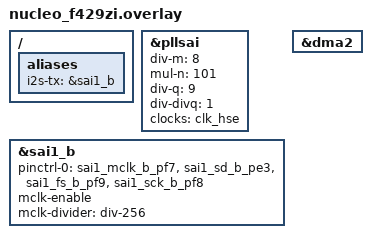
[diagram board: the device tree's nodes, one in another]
/*
 * Copyright (c) 2025 Mario Paja
 *
 * SPDX-License-Identifier: Apache-2.0
 */

/ {
	aliases {
		i2s-tx = &sai1_b;
	};
};

/* 43.836KHz (-0.37% Error) */
&pllsai{
	div-m = <8>;
	mul-n = <101>;
	div-q = <9>;
	div-divq = <1>;
	clocks = <&clk_hse>;
	status = "okay";
};

&sai1_b {
	pinctrl-0 = <&sai1_mclk_b_pf7 &sai1_sd_b_pe3 &sai1_fs_b_pf9 &sai1_sck_b_pf8>;
	pinctrl-names = "default";
	status = "okay";
	mclk-enable;
	mclk-divider = "div-256";
	dma-names = "tx";
};

&dma2 {
	status = "okay";
};
